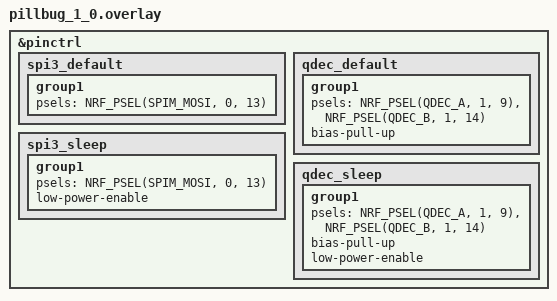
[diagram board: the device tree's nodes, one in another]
/*
 * Copyright (c) 2023 The ZMK Contributors
 *
 * SPDX-License-Identifier: MIT
 */

#include "bbpad-nrf52.dtsi"

&pinctrl {
    spi3_default: spi3_default {
        group1 {
            psels = <NRF_PSEL(SPIM_MOSI, 0, 13)>;
        };
    };

    spi3_sleep: spi3_sleep {
        group1 {
            psels = <NRF_PSEL(SPIM_MOSI, 0, 13)>;
            low-power-enable;
        };
    };

    qdec_default: qdec_default {
        group1 {
            psels = <NRF_PSEL(QDEC_A, 1, 9)>,
                    <NRF_PSEL(QDEC_B, 1, 14)>;
            bias-pull-up;
        };
    };

    qdec_sleep: qdec_sleep {
        group1 {
            psels = <NRF_PSEL(QDEC_A, 1, 9)>,
                    <NRF_PSEL(QDEC_B, 1, 14)>;
            bias-pull-up;
            low-power-enable;
        };
    };
};
